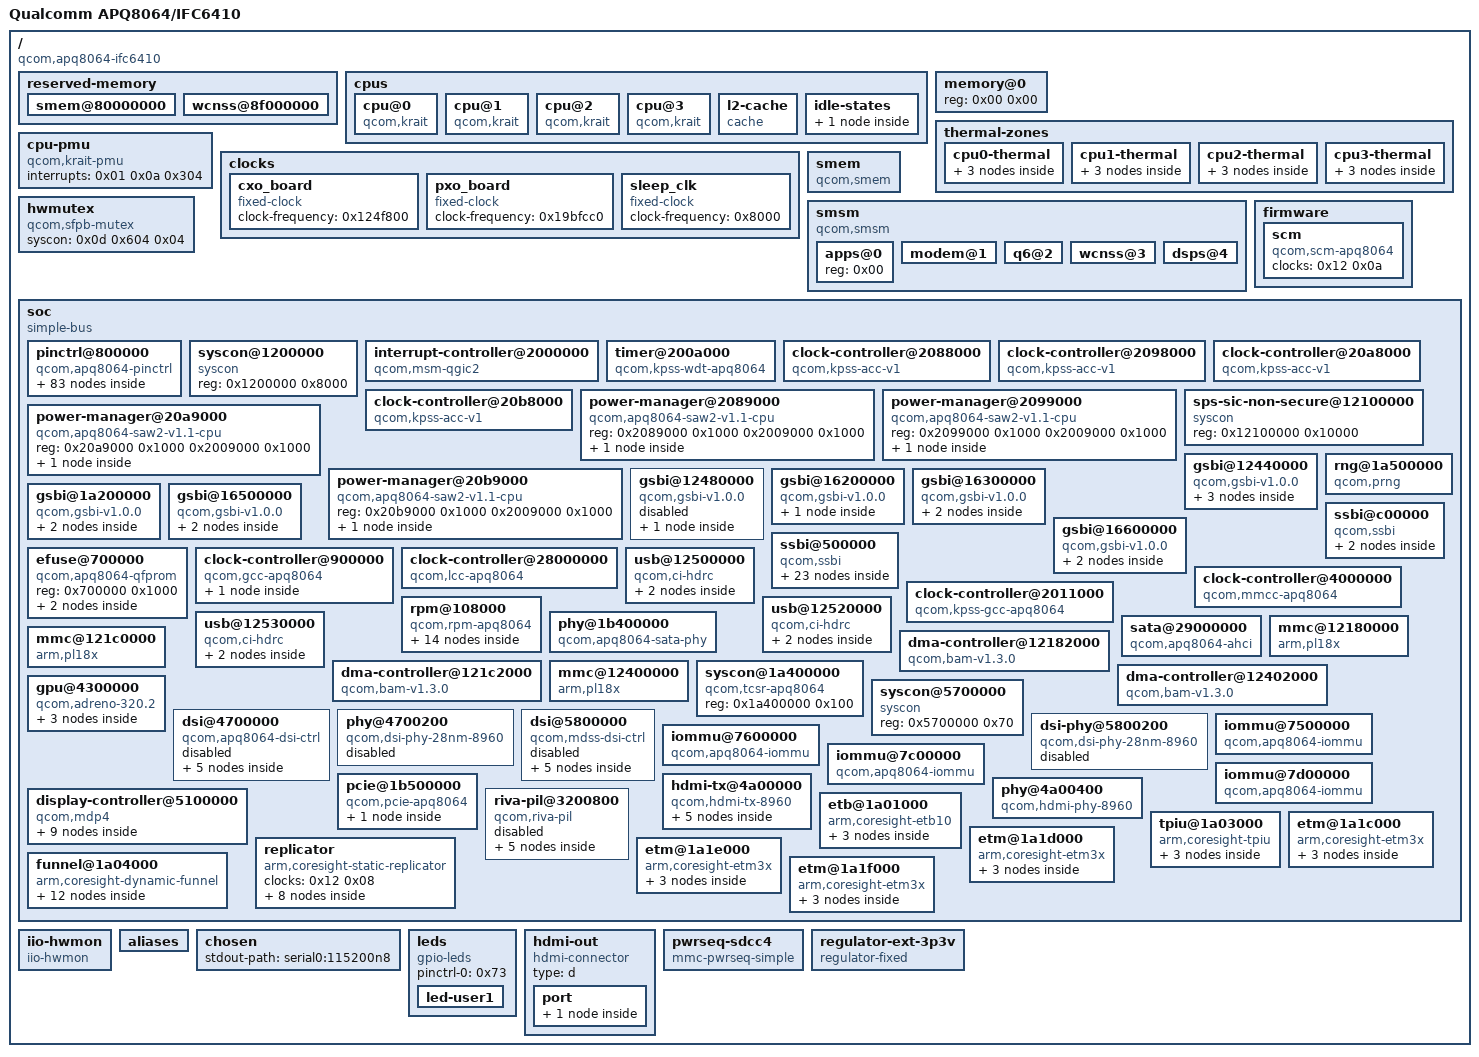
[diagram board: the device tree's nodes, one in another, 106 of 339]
/*
 * Copyright Linux Kernel Team
 *
 * SPDX-License-Identifier: GPL-2.0-only
 *
 * This file is derived from an intermediate build stage of the
 * Linux kernel. The licenses of all input files to this process
 * are compatible with GPL-2.0-only.
 */

/dts-v1/;

/ {
	#address-cells = <0x01>;
	#size-cells = <0x01>;
	model = "Qualcomm APQ8064/IFC6410";
	compatible = "qcom,apq8064-ifc6410", "qcom,apq8064";
	interrupt-parent = <0x01>;

	reserved-memory {
		#address-cells = <0x01>;
		#size-cells = <0x01>;
		ranges;

		smem@80000000 {
			reg = <0x80000000 0x200000>;
			no-map;
			phandle = <0x0e>;
		};

		wcnss@8f000000 {
			reg = <0x8f000000 0x700000>;
			no-map;
			phandle = <0x5d>;
		};
	};

	cpus {
		#address-cells = <0x01>;
		#size-cells = <0x00>;

		cpu@0 {
			compatible = "qcom,krait";
			enable-method = "qcom,kpss-acc-v1";
			device_type = "cpu";
			reg = <0x00>;
			next-level-cache = <0x02>;
			qcom,acc = <0x03>;
			qcom,saw = <0x04>;
			cpu-idle-states = <0x05>;
			phandle = <0x6a>;
		};

		cpu@1 {
			compatible = "qcom,krait";
			enable-method = "qcom,kpss-acc-v1";
			device_type = "cpu";
			reg = <0x01>;
			next-level-cache = <0x02>;
			qcom,acc = <0x06>;
			qcom,saw = <0x07>;
			cpu-idle-states = <0x05>;
			phandle = <0x6c>;
		};

		cpu@2 {
			compatible = "qcom,krait";
			enable-method = "qcom,kpss-acc-v1";
			device_type = "cpu";
			reg = <0x02>;
			next-level-cache = <0x02>;
			qcom,acc = <0x08>;
			qcom,saw = <0x09>;
			cpu-idle-states = <0x05>;
			phandle = <0x6e>;
		};

		cpu@3 {
			compatible = "qcom,krait";
			enable-method = "qcom,kpss-acc-v1";
			device_type = "cpu";
			reg = <0x03>;
			next-level-cache = <0x02>;
			qcom,acc = <0x0a>;
			qcom,saw = <0x0b>;
			cpu-idle-states = <0x05>;
			phandle = <0x70>;
		};

		l2-cache {
			compatible = "cache";
			cache-level = <0x02>;
			cache-unified;
			phandle = <0x02>;
		};

		idle-states {

			cpu-spc {
				compatible = "qcom,idle-state-spc", "arm,idle-state";
				entry-latency-us = <0x190>;
				exit-latency-us = <0x384>;
				min-residency-us = <0xbb8>;
				phandle = <0x05>;
			};
		};
	};

	memory@0 {
		device_type = "memory";
		reg = <0x00 0x00>;
	};

	thermal-zones {

		cpu0-thermal {
			polling-delay-passive = <0xfa>;
			polling-delay = <0x3e8>;
			thermal-sensors = <0x0c 0x07>;
			coefficients = <0x4af 0x00>;

			trips {

				trip0 {
					temperature = <0x124f8>;
					hysteresis = <0x7d0>;
					type = "passive";
				};

				trip1 {
					temperature = <0x1adb0>;
					hysteresis = <0x7d0>;
					type = "critical";
				};
			};
		};

		cpu1-thermal {
			polling-delay-passive = <0xfa>;
			polling-delay = <0x3e8>;
			thermal-sensors = <0x0c 0x08>;
			coefficients = <0x46c 0x00>;

			trips {

				trip0 {
					temperature = <0x124f8>;
					hysteresis = <0x7d0>;
					type = "passive";
				};

				trip1 {
					temperature = <0x1adb0>;
					hysteresis = <0x7d0>;
					type = "critical";
				};
			};
		};

		cpu2-thermal {
			polling-delay-passive = <0xfa>;
			polling-delay = <0x3e8>;
			thermal-sensors = <0x0c 0x09>;
			coefficients = <0x4af 0x00>;

			trips {

				trip0 {
					temperature = <0x124f8>;
					hysteresis = <0x7d0>;
					type = "passive";
				};

				trip1 {
					temperature = <0x1adb0>;
					hysteresis = <0x7d0>;
					type = "critical";
				};
			};
		};

		cpu3-thermal {
			polling-delay-passive = <0xfa>;
			polling-delay = <0x3e8>;
			thermal-sensors = <0x0c 0x0a>;
			coefficients = <0x46c 0x00>;

			trips {

				trip0 {
					temperature = <0x124f8>;
					hysteresis = <0x7d0>;
					type = "passive";
				};

				trip1 {
					temperature = <0x1adb0>;
					hysteresis = <0x7d0>;
					type = "critical";
				};
			};
		};
	};

	cpu-pmu {
		compatible = "qcom,krait-pmu";
		interrupts = <0x01 0x0a 0x304>;
	};

	clocks {

		cxo_board {
			compatible = "fixed-clock";
			#clock-cells = <0x00>;
			clock-frequency = <0x124f800>;
			phandle = <0x2d>;
		};

		pxo_board {
			compatible = "fixed-clock";
			#clock-cells = <0x00>;
			clock-frequency = <0x19bfcc0>;
			phandle = <0x16>;
		};

		sleep_clk {
			compatible = "fixed-clock";
			#clock-cells = <0x00>;
			clock-frequency = <0x8000>;
			phandle = <0x38>;
		};
	};

	hwmutex {
		compatible = "qcom,sfpb-mutex";
		syscon = <0x0d 0x604 0x04>;
		#hwlock-cells = <0x01>;
		phandle = <0x0f>;
	};

	smem {
		compatible = "qcom,smem";
		memory-region = <0x0e>;
		hwlocks = <0x0f 0x03>;
	};

	smsm {
		compatible = "qcom,smsm";
		#address-cells = <0x01>;
		#size-cells = <0x00>;
		qcom,ipc-1 = <0x10 0x08 0x04>;
		qcom,ipc-2 = <0x10 0x08 0x0e>;
		qcom,ipc-3 = <0x10 0x08 0x17>;
		qcom,ipc-4 = <0x11 0x4094 0x00>;

		apps@0 {
			reg = <0x00>;
			#qcom,smem-state-cells = <0x01>;
			phandle = <0x5f>;
		};

		modem@1 {
			reg = <0x01>;
			interrupts = <0x00 0x26 0x01>;
			interrupt-controller;
			#interrupt-cells = <0x02>;
		};

		q6@2 {
			reg = <0x02>;
			interrupts = <0x00 0x59 0x01>;
			interrupt-controller;
			#interrupt-cells = <0x02>;
		};

		wcnss@3 {
			reg = <0x03>;
			interrupts = <0x00 0xcc 0x01>;
			interrupt-controller;
			#interrupt-cells = <0x02>;
			phandle = <0x5c>;
		};

		dsps@4 {
			reg = <0x04>;
			interrupts = <0x00 0x89 0x01>;
			interrupt-controller;
			#interrupt-cells = <0x02>;
		};
	};

	firmware {

		scm {
			compatible = "qcom,scm-apq8064", "qcom,scm";
			clocks = <0x12 0x0a>;
			clock-names = "core";
		};
	};

	soc {
		#address-cells = <0x01>;
		#size-cells = <0x01>;
		ranges;
		compatible = "simple-bus";

		pinctrl@800000 {
			compatible = "qcom,apq8064-pinctrl";
			reg = <0x800000 0x4000>;
			gpio-controller;
			gpio-ranges = <0x13 0x00 0x00 0x5a>;
			#gpio-cells = <0x02>;
			interrupt-controller;
			#interrupt-cells = <0x02>;
			interrupts = <0x00 0x10 0x04>;
			pinctrl-names = "default";
			pinctrl-0 = <0x14>;
			phandle = <0x13>;

			sdc4-gpios {
				phandle = <0x46>;

				pios {
					pins = "gpio63", "gpio64", "gpio65", "gpio66", "gpio67", "gpio68";
					function = "sdc4";
				};
			};

			sdcc1-pin-active {
				phandle = <0x4a>;

				clk {
					pins = "sdc1_clk";
					drive-strengh = <0x10>;
					bias-disable;
				};

				cmd {
					pins = "sdc1_cmd";
					drive-strengh = <0x0a>;
					bias-pull-up;
				};

				data {
					pins = "sdc1_data";
					drive-strengh = <0x0a>;
					bias-pull-up;
				};
			};

			sdcc3-pin-active {

				clk {
					pins = "sdc3_clk";
					drive-strengh = <0x08>;
					bias-disable;
				};

				cmd {
					pins = "sdc3_cmd";
					drive-strengh = <0x08>;
					bias-pull-up;
				};

				data {
					pins = "sdc3_data";
					drive-strengh = <0x08>;
					bias-pull-up;
				};
			};

			ps_hold {
				phandle = <0x14>;

				mux {
					pins = "gpio78";
					function = "ps_hold";
				};
			};

			i2c1 {
				phandle = <0x18>;

				mux {
					pins = "gpio20", "gpio21";
					function = "gsbi1";
				};

				pinconf {
					pins = "gpio20", "gpio21";
					drive-strength = <0x10>;
					bias-disable;
				};
			};

			i2c1_pins_sleep {
				phandle = <0x19>;

				mux {
					pins = "gpio20", "gpio21";
					function = "gpio";
				};

				pinconf {
					pins = "gpio20", "gpio21";
					drive-strength = <0x02>;
					bias-disable;
				};
			};

			gsbi1_uart_2pins {

				mux {
					pins = "gpio18", "gpio19";
					function = "gsbi1";
				};
			};

			gsbi1_uart_4pins {

				mux {
					pins = "gpio18", "gpio19", "gpio20", "gpio21";
					function = "gsbi1";
				};
			};

			i2c2 {
				phandle = <0x1a>;

				mux {
					pins = "gpio24", "gpio25";
					function = "gsbi2";
				};

				pinconf {
					pins = "gpio24", "gpio25";
					drive-strength = <0x10>;
					bias-disable;
				};
			};

			i2c2_pins_sleep {
				phandle = <0x1b>;

				mux {
					pins = "gpio24", "gpio25";
					function = "gpio";
				};

				pinconf {
					pins = "gpio24", "gpio25";
					drive-strength = <0x02>;
					bias-disable;
				};
			};

			i2c3 {
				phandle = <0x1c>;

				mux {
					pins = "gpio8", "gpio9";
					function = "gsbi3";
				};

				pinconf {
					pins = "gpio8", "gpio9";
					drive-strength = <0x10>;
					bias-disable;
				};
			};

			i2c3_pins_sleep {
				phandle = <0x1d>;

				mux {
					pins = "gpio8", "gpio9";
					function = "gpio";
				};

				pinconf {
					pins = "gpio8", "gpio9";
					drive-strength = <0x02>;
					bias-disable;
				};
			};

			i2c4 {
				phandle = <0x1f>;

				mux {
					pins = "gpio12", "gpio13";
					function = "gsbi4";
				};

				pinconf {
					pins = "gpio12", "gpio13";
					drive-strength = <0x10>;
					bias-disable;
				};
			};

			i2c4_pins_sleep {
				phandle = <0x20>;

				mux {
					pins = "gpio12", "gpio13";
					function = "gpio";
				};

				pinconf {
					pins = "gpio12", "gpio13";
					drive-strength = <0x02>;
					bias-disable;
				};
			};

			spi5_default {
				phandle = <0x21>;

				pinmux {
					pins = "gpio51", "gpio52", "gpio54";
					function = "gsbi5";
				};

				pinmux_cs {
					function = "gpio";
					pins = "gpio53";
				};

				pinconf {
					pins = "gpio51", "gpio52", "gpio54";
					drive-strength = <0x10>;
					bias-disable;
				};

				pinconf_cs {
					pins = "gpio53";
					drive-strength = <0x10>;
					bias-disable;
					output-high;
				};
			};

			spi5_sleep {
				phandle = <0x22>;

				pinmux {
					function = "gpio";
					pins = "gpio51", "gpio52", "gpio53", "gpio54";
				};

				pinconf {
					pins = "gpio51", "gpio52", "gpio53", "gpio54";
					drive-strength = <0x02>;
					bias-pull-down;
				};
			};

			i2c6 {
				phandle = <0x24>;

				mux {
					pins = "gpio16", "gpio17";
					function = "gsbi6";
				};

				pinconf {
					pins = "gpio16", "gpio17";
					drive-strength = <0x10>;
					bias-disable;
				};
			};

			i2c6_pins_sleep {
				phandle = <0x25>;

				mux {
					pins = "gpio16", "gpio17";
					function = "gpio";
				};

				pinconf {
					pins = "gpio16", "gpio17";
					drive-strength = <0x02>;
					bias-disable;
				};
			};

			gsbi4-uart-pin-active-state {
				phandle = <0x1e>;

				rx-pins {
					pins = "gpio11";
					function = "gsbi4";
					drive-strength = <0x02>;
					bias-disable;
				};

				tx-pins {
					pins = "gpio10";
					function = "gsbi4";
					drive-strength = <0x04>;
					bias-disable;
				};
			};

			gsbi6_uart_2pins {

				mux {
					pins = "gpio14", "gpio15";
					function = "gsbi6";
				};
			};

			gsbi6_uart_4pins {
				phandle = <0x23>;

				mux {
					pins = "gpio14", "gpio15", "gpio16", "gpio17";
					function = "gsbi6";
				};
			};

			gsbi7_uart_2pins {
				phandle = <0x26>;

				mux {
					pins = "gpio82", "gpio83";
					function = "gsbi7";
				};
			};

			gsbi7_uart_4pins {

				mux {
					pins = "gpio82", "gpio83", "gpio84", "gpio85";
					function = "gsbi7";
				};
			};

			i2c7 {
				phandle = <0x27>;

				mux {
					pins = "gpio84", "gpio85";
					function = "gsbi7";
				};

				pinconf {
					pins = "gpio84", "gpio85";
					drive-strength = <0x10>;
					bias-disable;
				};
			};

			i2c7_pins_sleep {
				phandle = <0x28>;

				mux {
					pins = "gpio84", "gpio85";
					function = "gpio";
				};

				pinconf {
					pins = "gpio84", "gpio85";
					drive-strength = <0x02>;
					bias-disable;
				};
			};

			riva-fm-active {
				pins = "gpio14", "gpio15";
				function = "riva_fm";
			};

			riva-bt-active {
				pins = "gpio16", "gpio17";
				function = "riva_bt";
			};

			riva-wlan-active {
				pins = "gpio64", "gpio65", "gpio66", "gpio67", "gpio68";
				function = "riva_wlan";
				drive-strength = <0x06>;
				bias-pull-down;
			};

			hdmi-pinctrl {
				phandle = <0x55>;

				mux {
					pins = "gpio70", "gpio71", "gpio72";
					function = "hdmi";
				};

				pinconf_ddc {
					pins = "gpio70", "gpio71";
					bias-pull-up;
					drive-strength = <0x02>;
				};

				pinconf_hpd {
					pins = "gpio72";
					bias-pull-down;
					drive-strength = <0x10>;
				};
			};

			card_detect {
				phandle = <0x44>;

				mux {
					pins = "gpio26";
					function = "gpio";
					bias-disable;
				};
			};

			pcie_pinmux {
				phandle = <0x54>;

				mux {
					pins = "gpio27";
					function = "gpio";
				};

				conf {
					pins = "gpio27";
					drive-strength = <0x0c>;
					bias-disable;
				};
			};
		};

		syscon@1200000 {
			compatible = "syscon";
			reg = <0x1200000 0x8000>;
			phandle = <0x0d>;
		};

		interrupt-controller@2000000 {
			compatible = "qcom,msm-qgic2";
			interrupt-controller;
			#interrupt-cells = <0x03>;
			reg = <0x2000000 0x1000 0x2002000 0x1000>;
			phandle = <0x01>;
		};

		timer@200a000 {
			compatible = "qcom,kpss-wdt-apq8064", "qcom,kpss-timer", "qcom,msm-timer";
			interrupts = <0x01 0x01 0x301 0x01 0x02 0x301 0x01 0x03 0x301>;
			reg = <0x200a000 0x100>;
			clock-frequency = <0x19bfcc0>;
			cpu-offset = <0x80000>;
		};

		clock-controller@2088000 {
			compatible = "qcom,kpss-acc-v1";
			reg = <0x2088000 0x1000 0x2008000 0x1000>;
			clocks = <0x15 0x11f 0x16>;
			clock-names = "pll8_vote", "pxo";
			clock-output-names = "acpu0_aux";
			#clock-cells = <0x00>;
			phandle = <0x03>;
		};

		clock-controller@2098000 {
			compatible = "qcom,kpss-acc-v1";
			reg = <0x2098000 0x1000 0x2008000 0x1000>;
			clocks = <0x15 0x11f 0x16>;
			clock-names = "pll8_vote", "pxo";
			clock-output-names = "acpu1_aux";
			#clock-cells = <0x00>;
			phandle = <0x06>;
		};

		clock-controller@20a8000 {
			compatible = "qcom,kpss-acc-v1";
			reg = <0x20a8000 0x1000 0x2008000 0x1000>;
			clocks = <0x15 0x11f 0x16>;
			clock-names = "pll8_vote", "pxo";
			clock-output-names = "acpu2_aux";
			#clock-cells = <0x00>;
			phandle = <0x08>;
		};

		clock-controller@20b8000 {
			compatible = "qcom,kpss-acc-v1";
			reg = <0x20b8000 0x1000 0x2008000 0x1000>;
			clocks = <0x15 0x11f 0x16>;
			clock-names = "pll8_vote", "pxo";
			clock-output-names = "acpu3_aux";
			#clock-cells = <0x00>;
			phandle = <0x0a>;
		};

		power-manager@2089000 {
			compatible = "qcom,apq8064-saw2-v1.1-cpu", "qcom,saw2";
			reg = <0x2089000 0x1000 0x2009000 0x1000>;
			phandle = <0x04>;

			regulator {
				regulator-min-microvolt = <0xcf850>;
				regulator-max-microvolt = <0x13d620>;
			};
		};

		power-manager@2099000 {
			compatible = "qcom,apq8064-saw2-v1.1-cpu", "qcom,saw2";
			reg = <0x2099000 0x1000 0x2009000 0x1000>;
			phandle = <0x07>;

			regulator {
				regulator-min-microvolt = <0xcf850>;
				regulator-max-microvolt = <0x13d620>;
			};
		};

		power-manager@20a9000 {
			compatible = "qcom,apq8064-saw2-v1.1-cpu", "qcom,saw2";
			reg = <0x20a9000 0x1000 0x2009000 0x1000>;
			phandle = <0x09>;

			regulator {
				regulator-min-microvolt = <0xcf850>;
				regulator-max-microvolt = <0x13d620>;
			};
		};

		power-manager@20b9000 {
			compatible = "qcom,apq8064-saw2-v1.1-cpu", "qcom,saw2";
			reg = <0x20b9000 0x1000 0x2009000 0x1000>;
			phandle = <0x0b>;

			regulator {
				regulator-min-microvolt = <0xcf850>;
				regulator-max-microvolt = <0x13d620>;
			};
		};

		sps-sic-non-secure@12100000 {
			compatible = "syscon";
			reg = <0x12100000 0x10000>;
			phandle = <0x11>;
		};

		gsbi@12440000 {
			status = "okay";
			compatible = "qcom,gsbi-v1.0.0";
			cell-index = <0x01>;
			reg = <0x12440000 0x100>;
			clocks = <0x15 0x93>;
			clock-names = "iface";
			#address-cells = <0x01>;
			#size-cells = <0x01>;
			ranges;
			syscon-tcsr = <0x17>;
			qcom,mode = <0x02>;

			serial@12450000 {
				compatible = "qcom,msm-uartdm-v1.3", "qcom,msm-uartdm";
				reg = <0x12450000 0x100 0x12400000 0x03>;
				interrupts = <0x00 0xc1 0x04>;
				clocks = <0x15 0xa0 0x15 0x93>;
				clock-names = "core", "iface";
				status = "disabled";
			};

			i2c@12460000 {
				compatible = "qcom,i2c-qup-v1.1.1";
				pinctrl-0 = <0x18>;
				pinctrl-1 = <0x19>;
				pinctrl-names = "default", "sleep";
				reg = <0x12460000 0x1000>;
				interrupts = <0x00 0xc2 0x04>;
				clocks = <0x15 0xb8 0x15 0x93>;
				clock-names = "core", "iface";
				#address-cells = <0x01>;
				#size-cells = <0x00>;
				status = "okay";
				clock-frequency = <0x30d40>;

				eeprom@52 {
					compatible = "atmel,24c128";
					reg = <0x52>;
					pagesize = <0x20>;
				};
			};
		};

		gsbi@12480000 {
			status = "disabled";
			compatible = "qcom,gsbi-v1.0.0";
			cell-index = <0x02>;
			reg = <0x12480000 0x100>;
			clocks = <0x15 0x94>;
			clock-names = "iface";
			#address-cells = <0x01>;
			#size-cells = <0x01>;
			ranges;
			syscon-tcsr = <0x17>;

			i2c@124a0000 {
				compatible = "qcom,i2c-qup-v1.1.1";
				reg = <0x124a0000 0x1000>;
				pinctrl-0 = <0x1a>;
				pinctrl-1 = <0x1b>;
				pinctrl-names = "default", "sleep";
				interrupts = <0x00 0xc4 0x04>;
				clocks = <0x15 0xba 0x15 0x94>;
				clock-names = "core", "iface";
				#address-cells = <0x01>;
				#size-cells = <0x00>;
				status = "disabled";
			};
		};

		gsbi@16200000 {
			status = "okay";
			compatible = "qcom,gsbi-v1.0.0";
			cell-index = <0x03>;
			reg = <0x16200000 0x100>;
			clocks = <0x15 0x95>;
			clock-names = "iface";
			#address-cells = <0x01>;
			#size-cells = <0x01>;
			ranges;
			qcom,mode = <0x02>;

			i2c@16280000 {
				compatible = "qcom,i2c-qup-v1.1.1";
				pinctrl-0 = <0x1c>;
				pinctrl-1 = <0x1d>;
				pinctrl-names = "default", "sleep";
				reg = <0x16280000 0x1000>;
				interrupts = <0x00 0x97 0x04>;
				clocks = <0x15 0xbc 0x15 0x95>;
				clock-names = "core", "iface";
				#address-cells = <0x01>;
				#size-cells = <0x00>;
				status = "okay";
			};
		};

		gsbi@16300000 {
			status = "okay";
			compatible = "qcom,gsbi-v1.0.0";
			cell-index = <0x04>;
			reg = <0x16300000 0x03>;
			clocks = <0x15 0x96>;
			clock-names = "iface";
			#address-cells = <0x01>;
			#size-cells = <0x01>;
			ranges;
			qcom,mode = <0x02>;

			serial@16340000 {
				compatible = "qcom,msm-uartdm-v1.3", "qcom,msm-uartdm";
				reg = <0x16340000 0x100 0x16300000 0x03>;
				interrupts = <0x00 0x98 0x04>;
				pinctrl-0 = <0x1e>;
				pinctrl-names = "default";
				clocks = <0x15 0xa6 0x15 0x96>;
				clock-names = "core", "iface";
				status = "disabled";
			};

			i2c@16380000 {
				compatible = "qcom,i2c-qup-v1.1.1";
				pinctrl-0 = <0x1f>;
				pinctrl-1 = <0x20>;
				pinctrl-names = "default", "sleep";
				reg = <0x16380000 0x1000>;
				interrupts = <0x00 0x99 0x04>;
				clocks = <0x15 0xbe 0x15 0x96>;
				clock-names = "core", "iface";
				status = "okay";
			};
		};

		gsbi@1a200000 {
			status = "okay";
			compatible = "qcom,gsbi-v1.0.0";
			cell-index = <0x05>;
			reg = <0x1a200000 0x03>;
			clocks = <0x15 0x97>;
			clock-names = "iface";
			#address-cells = <0x01>;
			#size-cells = <0x01>;
			ranges;
			qcom,mode = <0x03>;

			serial@1a240000 {
				compatible = "qcom,msm-uartdm-v1.3", "qcom,msm-uartdm";
				reg = <0x1a240000 0x100 0x1a200000 0x03>;
				interrupts = <0x00 0x9a 0x04>;
				clocks = <0x15 0xa8 0x15 0x97>;
				clock-names = "core", "iface";
				status = "disabled";
			};

			spi@1a280000 {
				compatible = "qcom,spi-qup-v1.1.1";
				reg = <0x1a280000 0x1000>;
				interrupts = <0x00 0x9b 0x04>;
				pinctrl-0 = <0x21>;
				pinctrl-1 = <0x22>;
				pinctrl-names = "default", "sleep";
				clocks = <0x15 0xc0 0x15 0x97>;
				clock-names = "core", "iface";
				status = "okay";
				#address-cells = <0x01>;
				#size-cells = <0x00>;
				num-cs = <0x01>;
				cs-gpios = <0x13 0x35 0x00>;
			};
		};

		gsbi@16500000 {
			status = "okay";
			compatible = "qcom,gsbi-v1.0.0";
			cell-index = <0x06>;
			reg = <0x16500000 0x03>;
			clocks = <0x15 0x98>;
			clock-names = "iface";
			#address-cells = <0x01>;
			#size-cells = <0x01>;
			ranges;
			qcom,mode = <0x04>;

			serial@16540000 {
				compatible = "qcom,msm-uartdm-v1.3", "qcom,msm-uartdm";
				reg = <0x16540000 0x100 0x16500000 0x03>;
				interrupts = <0x00 0x9c 0x04>;
				clocks = <0x15 0xaa 0x15 0x98>;
				clock-names = "core", "iface";
				status = "okay";
				pinctrl-names = "default";
				pinctrl-0 = <0x23>;
			};

			i2c@16580000 {
				compatible = "qcom,i2c-qup-v1.1.1";
				pinctrl-0 = <0x24>;
				pinctrl-1 = <0x25>;
				pinctrl-names = "default", "sleep";
				reg = <0x16580000 0x1000>;
				interrupts = <0x00 0x9d 0x04>;
				clocks = <0x15 0xc2 0x15 0x98>;
				clock-names = "core", "iface";
				status = "disabled";
			};
		};

		gsbi@16600000 {
			status = "okay";
			compatible = "qcom,gsbi-v1.0.0";
			cell-index = <0x07>;
			reg = <0x16600000 0x100>;
			clocks = <0x15 0x99>;
			clock-names = "iface";
			#address-cells = <0x01>;
			#size-cells = <0x01>;
			ranges;
			syscon-tcsr = <0x17>;
			qcom,mode = <0x06>;

			serial@16640000 {
				compatible = "qcom,msm-uartdm-v1.3", "qcom,msm-uartdm";
				reg = <0x16640000 0x1000 0x16600000 0x1000>;
				interrupts = <0x00 0x9e 0x04>;
				clocks = <0x15 0xac 0x15 0x99>;
				clock-names = "core", "iface";
				status = "okay";
				pinctrl-names = "default";
				pinctrl-0 = <0x26>;
			};

			i2c@16680000 {
				compatible = "qcom,i2c-qup-v1.1.1";
				pinctrl-0 = <0x27>;
				pinctrl-1 = <0x28>;
				pinctrl-names = "default", "sleep";
				reg = <0x16680000 0x1000>;
				interrupts = <0x00 0x9f 0x04>;
				clocks = <0x15 0xc4 0x15 0x99>;
				clock-names = "core", "iface";
				status = "disabled";
			};
		};

		rng@1a500000 {
			compatible = "qcom,prng";
			reg = <0x1a500000 0x200>;
			clocks = <0x15 0x108>;
			clock-names = "core";
		};

		ssbi@c00000 {
			compatible = "qcom,ssbi";
			reg = <0xc00000 0x1000>;
			qcom,controller-type = "pmic-arbiter";

			pmic {
				compatible = "qcom,pm8821";
				interrupt-controller;
				#interrupt-cells = <0x02>;
				#address-cells = <0x01>;
				#size-cells = <0x00>;
				interrupts-extended = <0x13 0x4c 0x08>;

				mpps@50 {
					compatible = "qcom,pm8821-mpp", "qcom,ssbi-mpp";
					reg = <0x50>;
					gpio-controller;
					#gpio-cells = <0x02>;
					gpio-ranges = <0x29 0x00 0x00 0x04>;
					interrupt-controller;
					#interrupt-cells = <0x02>;
					phandle = <0x29>;
				};
			};
		};

		ssbi@500000 {
			compatible = "qcom,ssbi";
			reg = <0x500000 0x1000>;
			qcom,controller-type = "pmic-arbiter";

			pmic {
				compatible = "qcom,pm8921";
				#interrupt-cells = <0x02>;
				interrupt-controller;
				#address-cells = <0x01>;
				#size-cells = <0x00>;
				interrupts-extended = <0x13 0x4a 0x08>;
				phandle = <0x2a>;

				pwrkey@1c {
					compatible = "qcom,pm8921-pwrkey";
					reg = <0x1c>;
					interrupts-extended = <0x2a 0x32 0x01 0x2a 0x33 0x01>;
					debounce = <0x3d09>;
					pull-up;
				};

				mpps@50 {
					compatible = "qcom,pm8921-mpp", "qcom,ssbi-mpp";
					reg = <0x50>;
					gpio-controller;
					#gpio-cells = <0x02>;
					gpio-ranges = <0x2b 0x00 0x00 0x0c>;
					interrupt-controller;
					#interrupt-cells = <0x02>;
					phandle = <0x2b>;
				};

				rtc@11d {
					compatible = "qcom,pm8921-rtc";
					reg = <0x11d>;
					interrupts-extended = <0x2a 0x27 0x01>;
					allow-set-time;
				};

				keypad@148 {
					compatible = "qcom,pm8921-keypad";
					reg = <0x148>;
					interrupts-extended = <0x2a 0x4a 0x01 0x2a 0x4b 0x01>;
					debounce = <0x0f>;
					scan-delay = <0x20>;
					row-hold = <0x1656c>;
					status = "disabled";
				};

				gpio@150 {
					compatible = "qcom,pm8921-gpio", "qcom,ssbi-gpio";
					reg = <0x150>;
					interrupt-controller;
					#interrupt-cells = <0x02>;
					gpio-controller;
					gpio-ranges = <0x2c 0x00 0x00 0x2c>;
					#gpio-cells = <0x02>;
					phandle = <0x2c>;

					wlan-gpios-state {
						phandle = <0x75>;

						pinconf {
							pins = "gpio43";
							function = "normal";
							bias-disable;
							power-source = <0x02>;
						};
					};

					nled-state {
						phandle = <0x73>;

						pinconf {
							pins = "gpio18";
							function = "normal";
							bias-disable;
							power-source = <0x02>;
						};
					};
				};

				xoadc@197 {
					compatible = "qcom,pm8921-adc";
					reg = <0x197>;
					interrupts-extended = <0x2a 0x4e 0x01>;
					#address-cells = <0x02>;
					#size-cells = <0x00>;
					#io-channel-cells = <0x02>;
					phandle = <0x72>;

					adc-channel@0 {
						reg = <0x00 0x00>;
					};

					adc-channel@1 {
						reg = <0x00 0x01>;
					};

					adc-channel@2 {
						reg = <0x00 0x02>;
					};

					adc-channel@4 {
						reg = <0x00 0x04>;
					};

					adc-channel@8 {
						reg = <0x00 0x08>;
					};

					adc-channel@9 {
						reg = <0x00 0x09>;
					};

					adc-channel@a {
						reg = <0x00 0x0a>;
					};

					adc-channel@b {
						reg = <0x00 0x0b>;
					};

					adc-channel@c {
						reg = <0x00 0x0c>;
					};

					adc-channel@d {
						reg = <0x00 0x0d>;
					};

					adc-channel@e {
						reg = <0x00 0x0e>;
					};

					adc-channel@f {
						reg = <0x00 0x0f>;
					};
				};
			};
		};

		efuse@700000 {
			compatible = "qcom,apq8064-qfprom", "qcom,qfprom";
			reg = <0x700000 0x1000>;
			#address-cells = <0x01>;
			#size-cells = <0x01>;

			calib@404 {
				reg = <0x404 0x10>;
				phandle = <0x2f>;
			};

			backup_calib@414 {
				reg = <0x414 0x10>;
				phandle = <0x30>;
			};
		};

		clock-controller@900000 {
			compatible = "qcom,gcc-apq8064", "syscon";
			reg = <0x900000 0x4000>;
			#clock-cells = <0x01>;
			#reset-cells = <0x01>;
			clocks = <0x2d 0x16 0x2e 0x00>;
			clock-names = "cxo", "pxo", "pll4";
			phandle = <0x15>;

			thermal-sensor {
				compatible = "qcom,msm8960-tsens";
				nvmem-cells = <0x2f 0x30>;
				nvmem-cell-names = "calib", "calib_backup";
				interrupts = <0x00 0xb2 0x04>;
				interrupt-names = "uplow";
				#qcom,sensors = <0x0b>;
				#thermal-sensor-cells = <0x01>;
				phandle = <0x0c>;
			};
		};

		clock-controller@28000000 {
			compatible = "qcom,lcc-apq8064";
			reg = <0x28000000 0x1000>;
			#clock-cells = <0x01>;
			#reset-cells = <0x01>;
			clocks = <0x16 0x15 0x118 0x00 0x00 0x00 0x00 0x00 0x00>;
			clock-names = "pxo", "pll4_vote", "mi2s_codec_clk", "codec_i2s_mic_codec_clk", "spare_i2s_mic_codec_clk", "codec_i2s_spkr_codec_clk", "spare_i2s_spkr_codec_clk", "pcm_codec_clk";
			phandle = <0x2e>;
		};

		clock-controller@4000000 {
			compatible = "qcom,mmcc-apq8064";
			reg = <0x4000000 0x1000>;
			#clock-cells = <0x01>;
			#power-domain-cells = <0x01>;
			#reset-cells = <0x01>;
			clocks = <0x16 0x15 0x116 0x15 0x11f 0x31 0x01 0x31 0x00 0x32 0x01 0x32 0x00 0x33>;
			clock-names = "pxo", "pll3", "pll8_vote", "dsi1pll", "dsi1pllbyte", "dsi2pll", "dsi2pllbyte", "hdmipll";
			phandle = <0x4d>;
		};

		clock-controller@2011000 {
			compatible = "qcom,kpss-gcc-apq8064", "qcom,kpss-gcc", "syscon";
			reg = <0x2011000 0x1000>;
			clocks = <0x15 0x11f 0x16>;
			clock-names = "pll8_vote", "pxo";
			#clock-cells = <0x00>;
			phandle = <0x10>;
		};

		rpm@108000 {
			compatible = "qcom,rpm-apq8064";
			reg = <0x108000 0x1000>;
			qcom,ipc = <0x10 0x08 0x02>;
			interrupts = <0x00 0x13 0x01 0x00 0x15 0x01 0x00 0x16 0x01>;
			interrupt-names = "ack", "err", "wakeup";

			clock-controller {
				compatible = "qcom,rpmcc-apq8064", "qcom,rpmcc";
				#clock-cells = <0x01>;
				clocks = <0x16 0x2d>;
				clock-names = "pxo", "cxo";
				phandle = <0x12>;
			};

			regulators {
				compatible = "qcom,rpm-pm8921-regulators";
				vin_lvs1_3_6-supply = <0x34>;
				vin_lvs2-supply = <0x35>;
				vin_lvs4_5_7-supply = <0x34>;
				vdd_l1_l2_l12_l18-supply = <0x34>;
				vdd_l24-supply = <0x35>;
				vdd_l25-supply = <0x35>;
				vdd_l26-supply = <0x36>;
				vdd_l27-supply = <0x36>;
				vdd_l28-supply = <0x36>;

				s1 {
					regulator-always-on;
					regulator-min-microvolt = <0x12b128>;
					regulator-max-microvolt = <0x12b128>;
					qcom,switch-mode-frequency = <0x30d400>;
					bias-pull-down;
					phandle = <0x35>;
				};

				s3 {
					regulator-min-microvolt = <0xf4240>;
					regulator-max-microvolt = <0x155cc0>;
					qcom,switch-mode-frequency = "", "I>";
					phandle = <0x52>;
				};

				s4 {
					regulator-min-microvolt = <0x1b7740>;
					regulator-max-microvolt = <0x1b7740>;
					qcom,switch-mode-frequency = <0x30d400>;
					phandle = <0x34>;
				};

				s7 {
					regulator-min-microvolt = <0x13d620>;
					regulator-max-microvolt = <0x13d620>;
					qcom,switch-mode-frequency = <0x30d400>;
					phandle = <0x36>;
				};

				l3 {
					regulator-min-microvolt = <0x2e8a10>;
					regulator-max-microvolt = <0x325aa0>;
					bias-pull-down;
					phandle = <0x3a>;
				};

				l4 {
					regulator-min-microvolt = <0xf4240>;
					regulator-max-microvolt = <0x1b7740>;
					bias-pull-down;
					phandle = <0x3b>;
				};

				l5 {
					regulator-min-microvolt = <0x29f630>;
					regulator-max-microvolt = <0x2dc6c0>;
					bias-pull-down;
					phandle = <0x4c>;
				};

				l6 {
					regulator-min-microvolt = <0x2d0370>;
					regulator-max-microvolt = <0x2d0370>;
					bias-pull-down;
					phandle = <0x43>;
				};

				l23 {
					regulator-min-microvolt = <0x19f0a0>;
					regulator-max-microvolt = <0x1cfde0>;
					bias-pull-down;
					phandle = <0x3e>;
				};

				lvs1 {
					bias-pull-down;
					phandle = <0x48>;
				};

				lvs6 {
					bias-pull-down;
					phandle = <0x53>;
				};

				hdmi-switch {
					bias-pull-down;
					phandle = <0x56>;
				};
			};
		};

		usb@12500000 {
			compatible = "qcom,ci-hdrc";
			reg = <0x12500000 0x200 0x12500200 0x200>;
			interrupts = <0x00 0x64 0x04>;
			clocks = <0x15 0x80 0x15 0x7e>;
			clock-names = "core", "iface";
			assigned-clocks = <0x15 0x80>;
			assigned-clock-rates = <0x3938700>;
			resets = <0x15 0x40>;
			reset-names = "core";
			phy_type = "ulpi";
			ahb-burst-config = <0x00>;
			phys = <0x37>;
			phy-names = "usb-phy";
			status = "okay";
			#reset-cells = <0x01>;
			dr_mode = "otg";
			phandle = <0x39>;

			ulpi {

				phy {
					compatible = "qcom,usb-hs-phy-apq8064", "qcom,usb-hs-phy";
					clocks = <0x38 0x2d>;
					clock-names = "sleep", "ref";
					resets = <0x39 0x00>;
					reset-names = "por";
					#phy-cells = <0x00>;
					v3p3-supply = <0x3a>;
					v1p8-supply = <0x3b>;
					phandle = <0x37>;
				};
			};
		};

		usb@12520000 {
			compatible = "qcom,ci-hdrc";
			reg = <0x12520000 0x200 0x12520200 0x200>;
			interrupts = <0x00 0xbc 0x04>;
			clocks = <0x15 0x129 0x15 0x127>;
			clock-names = "core", "iface";
			assigned-clocks = <0x15 0x129>;
			assigned-clock-rates = <0x3938700>;
			resets = <0x15 0x64>;
			reset-names = "core";
			phy_type = "ulpi";
			ahb-burst-config = <0x00>;
			phys = <0x3c>;
			phy-names = "usb-phy";
			status = "okay";
			#reset-cells = <0x01>;
			dr_mode = "host";
			phandle = <0x3d>;

			ulpi {

				phy {
					compatible = "qcom,usb-hs-phy-apq8064", "qcom,usb-hs-phy";
					#phy-cells = <0x00>;
					clocks = <0x38 0x2d>;
					clock-names = "sleep", "ref";
					resets = <0x3d 0x00>;
					reset-names = "por";
					v3p3-supply = <0x3a>;
					v1p8-supply = <0x3e>;
					phandle = <0x3c>;
				};
			};
		};

		usb@12530000 {
			compatible = "qcom,ci-hdrc";
			reg = <0x12530000 0x200 0x12530200 0x200>;
			interrupts = <0x00 0xd7 0x04>;
			clocks = <0x15 0x12c 0x15 0x12a>;
			clock-names = "core", "iface";
			assigned-clocks = <0x15 0x12c>;
			assigned-clock-rates = <0x3938700>;
			resets = <0x15 0x65>;
			reset-names = "core";
			phy_type = "ulpi";
			ahb-burst-config = <0x00>;
			phys = <0x3f>;
			phy-names = "usb-phy";
			status = "okay";
			#reset-cells = <0x01>;
			dr_mode = "host";
			phandle = <0x40>;

			ulpi {

				phy {
					compatible = "qcom,usb-hs-phy-apq8064", "qcom,usb-hs-phy";
					#phy-cells = <0x00>;
					clocks = <0x38 0x2d>;
					clock-names = "sleep", "ref";
					resets = <0x40 0x00>;
					reset-names = "por";
					v3p3-supply = <0x3a>;
					v1p8-supply = <0x3e>;
					phandle = <0x3f>;
				};
			};
		};

		phy@1b400000 {
			compatible = "qcom,apq8064-sata-phy";
			status = "okay";
			reg = <0x1b400000 0x200>;
			reg-names = "phy_mem";
			clocks = <0x15 0x12d>;
			clock-names = "cfg";
			#phy-cells = <0x00>;
			phandle = <0x41>;
		};

		sata@29000000 {
			compatible = "qcom,apq8064-ahci", "generic-ahci";
			status = "okay";
			reg = <0x29000000 0x180>;
			interrupts = <0x00 0xd1 0x04>;
			clocks = <0x15 0x3b 0x15 0xed 0x15 0x12e 0x15 0xef 0x15 0xf0>;
			clock-names = "slave_iface", "iface", "bus", "rxoob", "core_pmalive";
			assigned-clocks = <0x15 0xef 0x15 0xf0>;
			assigned-clock-rates = <0x5f5e100 0x5f5e100>;
			phys = <0x41>;
			phy-names = "sata-phy";
			ports-implemented = <0x01>;
			target-supply = <0x34>;
		};

		mmc@12180000 {
			compatible = "arm,pl18x", "arm,primecell";
			arm,primecell-periphid = <0x51180>;
			status = "okay";
			reg = <0x12180000 0x2000>;
			interrupts = <0x00 0x66 0x04>;
			clocks = <0x15 0x7a 0x15 0x70>;
			clock-names = "mclk", "apb_pclk";
			bus-width = <0x04>;
			cap-sd-highspeed;
			cap-mmc-highspeed;
			max-frequency = <0xb71b000>;
			no-1-8-v;
			dmas = <0x42 0x02 0x42 0x01>;
			dma-names = "tx", "rx";
			vmmc-supply = <0x43>;
			pinctrl-names = "default";
			pinctrl-0 = <0x44>;
			cd-gpios = <0x13 0x1a 0x01>;
		};

		dma-controller@12182000 {
			compatible = "qcom,bam-v1.3.0";
			reg = <0x12182000 0x8000>;
			interrupts = <0x00 0x60 0x04>;
			clocks = <0x15 0x70>;
			clock-names = "bam_clk";
			#dma-cells = <0x01>;
			qcom,ee = <0x00>;
			phandle = <0x42>;
		};

		mmc@121c0000 {
			compatible = "arm,pl18x", "arm,primecell";
			arm,primecell-periphid = <0x51180>;
			status = "okay";
			reg = <0x121c0000 0x2000>;
			interrupts = <0x00 0x65 0x04>;
			clocks = <0x15 0x7b 0x15 0x71>;
			clock-names = "mclk", "apb_pclk";
			bus-width = <0x04>;
			cap-sd-highspeed;
			cap-mmc-highspeed;
			max-frequency = <0x2dc6c00>;
			dmas = <0x45 0x02 0x45 0x01>;
			dma-names = "tx", "rx";
			pinctrl-names = "default";
			pinctrl-0 = <0x46>;
			vmmc-supply = <0x47>;
			vqmmc-supply = <0x48>;
			mmc-pwrseq = <0x49>;
		};

		dma-controller@121c2000 {
			compatible = "qcom,bam-v1.3.0";
			reg = <0x121c2000 0x8000>;
			interrupts = <0x00 0x5f 0x04>;
			clocks = <0x15 0x71>;
			clock-names = "bam_clk";
			#dma-cells = <0x01>;
			qcom,ee = <0x00>;
			phandle = <0x45>;
		};

		mmc@12400000 {
			status = "okay";
			compatible = "arm,pl18x", "arm,primecell";
			pinctrl-names = "default";
			pinctrl-0 = <0x4a>;
			arm,primecell-periphid = <0x51180>;
			reg = <0x12400000 0x2000>;
			interrupts = <0x00 0x68 0x04>;
			clocks = <0x15 0x78 0x15 0x6e>;
			clock-names = "mclk", "apb_pclk";
			bus-width = <0x08>;
			max-frequency = <0x5b8d800>;
			non-removable;
			cap-sd-highspeed;
			cap-mmc-highspeed;
			dmas = <0x4b 0x02 0x4b 0x01>;
			dma-names = "tx", "rx";
			vmmc-supply = <0x4c>;
			vqmmc-supply = <0x34>;
		};

		dma-controller@12402000 {
			compatible = "qcom,bam-v1.3.0";
			reg = <0x12402000 0x8000>;
			interrupts = <0x00 0x62 0x04>;
			clocks = <0x15 0x6e>;
			clock-names = "bam_clk";
			#dma-cells = <0x01>;
			qcom,ee = <0x00>;
			phandle = <0x4b>;
		};

		syscon@1a400000 {
			compatible = "qcom,tcsr-apq8064", "syscon";
			reg = <0x1a400000 0x100>;
			phandle = <0x17>;
		};

		gpu@4300000 {
			compatible = "qcom,adreno-320.2", "qcom,adreno";
			reg = <0x4300000 0x20000>;
			reg-names = "kgsl_3d0_reg_memory";
			interrupts = <0x00 0x50 0x04>;
			interrupt-names = "kgsl_3d0_irq";
			clock-names = "core", "iface", "mem", "mem_iface";
			clocks = <0x4d 0x47 0x4d 0x16 0x4d 0x21 0x4d 0x13>;
			iommus = <0x4e 0x00 0x4e 0x01 0x4e 0x02 0x4e 0x03 0x4e 0x04 0x4e 0x05 0x4e 0x06 0x4e 0x07 0x4e 0x08 0x4e 0x09 0x4e 0x0a 0x4e 0x0b 0x4e 0x0c 0x4e 0x0d 0x4e 0x0e 0x4e 0x0f 0x4e 0x10 0x4e 0x11 0x4e 0x12 0x4e 0x13 0x4e 0x14 0x4e 0x15 0x4e 0x16 0x4e 0x17 0x4e 0x18 0x4e 0x19 0x4e 0x1a 0x4e 0x1b 0x4e 0x1c 0x4e 0x1d 0x4e 0x1e 0x4e 0x1f 0x4f 0x00 0x4f 0x01 0x4f 0x02 0x4f 0x03 0x4f 0x04 0x4f 0x05 0x4f 0x06 0x4f 0x07 0x4f 0x08 0x4f 0x09 0x4f 0x0a 0x4f 0x0b 0x4f 0x0c 0x4f 0x0d 0x4f 0x0e 0x4f 0x0f 0x4f 0x10 0x4f 0x11 0x4f 0x12 0x4f 0x13 0x4f 0x14 0x4f 0x15 0x4f 0x16 0x4f 0x17 0x4f 0x18 0x4f 0x19 0x4f 0x1a 0x4f 0x1b 0x4f 0x1c 0x4f 0x1d 0x4f 0x1e 0x4f 0x1f>;
			operating-points-v2 = <0x50>;

			opp-table {
				compatible = "operating-points-v2";
				phandle = <0x50>;

				opp-450000000 {
					opp-hz = <0x00 0x1ad27480>;
				};

				opp-27000000 {
					opp-hz = <0x00 0x19bfcc0>;
				};
			};
		};

		syscon@5700000 {
			compatible = "syscon";
			reg = <0x5700000 0x70>;
			phandle = <0x51>;
		};

		dsi@4700000 {
			compatible = "qcom,apq8064-dsi-ctrl", "qcom,mdss-dsi-ctrl";
			#address-cells = <0x01>;
			#size-cells = <0x00>;
			interrupts = <0x00 0x52 0x04>;
			reg = <0x4700000 0x200>;
			reg-names = "dsi_ctrl";
			clocks = <0x4d 0x11 0x4d 0x08 0x4d 0x04 0x4d 0x39 0x4d 0x54 0x4d 0x6a 0x4d 0x58>;
			clock-names = "iface", "bus", "core_mmss", "src", "byte", "pixel", "core";
			assigned-clocks = <0x4d 0x53 0x4d 0x57 0x4d 0x38 0x4d 0x69>;
			assigned-clock-parents = <0x31 0x00 0x31 0x00 0x31 0x01 0x31 0x01>;
			syscon-sfpb = <0x51>;
			phys = <0x31>;
			status = "disabled";

			ports {
				#address-cells = <0x01>;
				#size-cells = <0x00>;

				port@0 {
					reg = <0x00>;

					endpoint {
					};
				};

				port@1 {
					reg = <0x01>;

					endpoint {
					};
				};
			};
		};

		phy@4700200 {
			compatible = "qcom,dsi-phy-28nm-8960";
			#clock-cells = <0x01>;
			#phy-cells = <0x00>;
			reg = <0x4700200 0x100 0x4700300 0x200 0x4700500 0x5c>;
			reg-names = "dsi_pll", "dsi_phy", "dsi_phy_regulator";
			clock-names = "iface", "ref";
			clocks = <0x4d 0x11 0x16>;
			status = "disabled";
			phandle = <0x31>;
		};

		dsi@5800000 {
			compatible = "qcom,mdss-dsi-ctrl";
			interrupts = <0x00 0xa6 0x04>;
			reg = <0x5800000 0x200>;
			reg-names = "dsi_ctrl";
			clocks = <0x4d 0x09 0x4d 0x05 0x4d 0x04 0x4d 0x52 0x4d 0x56 0x4d 0x50 0x4d 0x5a>;
			clock-names = "iface", "bus", "core_mmss", "src", "byte", "pixel", "core";
			assigned-clocks = <0x4d 0x55 0x4d 0x59 0x4d 0x51 0x4d 0x4f>;
			assigned-clock-parents = <0x32 0x00 0x32 0x00 0x32 0x01 0x32 0x01>;
			syscon-sfpb = <0x51>;
			phys = <0x32>;
			#address-cells = <0x01>;
			#size-cells = <0x00>;
			status = "disabled";

			ports {
				#address-cells = <0x01>;
				#size-cells = <0x00>;

				port@0 {
					reg = <0x00>;

					endpoint {
					};
				};

				port@1 {
					reg = <0x01>;

					endpoint {
					};
				};
			};
		};

		dsi-phy@5800200 {
			compatible = "qcom,dsi-phy-28nm-8960";
			reg = <0x5800200 0x100 0x5800300 0x200 0x5800500 0x5c>;
			reg-names = "dsi_pll", "dsi_phy", "dsi_phy_regulator";
			clock-names = "iface", "ref";
			clocks = <0x4d 0x09 0x16>;
			#clock-cells = <0x01>;
			#phy-cells = <0x00>;
			status = "disabled";
			phandle = <0x32>;
		};

		iommu@7500000 {
			compatible = "qcom,apq8064-iommu";
			#iommu-cells = <0x01>;
			clock-names = "smmu_pclk", "iommu_clk";
			clocks = <0x4d 0x0b 0x4d 0x1e>;
			reg = <0x7500000 0x100000>;
			interrupts = <0x00 0x3f 0x04 0x00 0x40 0x04>;
			qcom,ncb = <0x02>;
			phandle = <0x59>;
		};

		iommu@7600000 {
			compatible = "qcom,apq8064-iommu";
			#iommu-cells = <0x01>;
			clock-names = "smmu_pclk", "iommu_clk";
			clocks = <0x4d 0x0b 0x4d 0x1e>;
			reg = <0x7600000 0x100000>;
			interrupts = <0x00 0x3d 0x04 0x00 0x3e 0x04>;
			qcom,ncb = <0x02>;
			phandle = <0x5a>;
		};

		iommu@7c00000 {
			compatible = "qcom,apq8064-iommu";
			#iommu-cells = <0x01>;
			clock-names = "smmu_pclk", "iommu_clk";
			clocks = <0x4d 0x0b 0x4d 0x21>;
			reg = <0x7c00000 0x100000>;
			interrupts = <0x00 0x45 0x04 0x00 0x46 0x04>;
			qcom,ncb = <0x03>;
			phandle = <0x4e>;
		};

		iommu@7d00000 {
			compatible = "qcom,apq8064-iommu";
			#iommu-cells = <0x01>;
			clock-names = "smmu_pclk", "iommu_clk";
			clocks = <0x4d 0x0b 0x4d 0x21>;
			reg = <0x7d00000 0x100000>;
			interrupts = <0x00 0xd2 0x04 0x00 0xd3 0x04>;
			qcom,ncb = <0x03>;
			phandle = <0x4f>;
		};

		pcie@1b500000 {
			compatible = "qcom,pcie-apq8064";
			reg = <0x1b500000 0x1000 0x1b502000 0x80 0x1b600000 0x100 0xff00000 0x100000>;
			reg-names = "dbi", "elbi", "parf", "config";
			device_type = "pci";
			linux,pci-domain = <0x00>;
			bus-range = <0x00 0xff>;
			num-lanes = <0x01>;
			#address-cells = <0x03>;
			#size-cells = <0x02>;
			ranges = <0x81000000 0x00 0x00 0xfe00000 0x00 0x100000 0x82000000 0x00 0x8000000 0x8000000 0x00 0x7e00000>;
			interrupts = <0x00 0xee 0x04>;
			interrupt-names = "msi";
			#interrupt-cells = <0x01>;
			interrupt-map-mask = <0x00 0x00 0x00 0x07>;
			interrupt-map = <0x00 0x00 0x00 0x01 0x01 0x00 0x24 0x04 0x00 0x00 0x00 0x02 0x01 0x00 0x25 0x04 0x00 0x00 0x00 0x03 0x01 0x00 0x26 0x04 0x00 0x00 0x00 0x04 0x01 0x00 0x27 0x04>;
			clocks = <0x15 0x2b 0x15 0x2e 0x15 0x2d>;
			clock-names = "core", "iface", "phy";
			resets = <0x15 0x6c 0x15 0x6b 0x15 0x6a 0x15 0x69 0x15 0x68>;
			reset-names = "axi", "ahb", "por", "pci", "phy";
			status = "okay";
			vdda-supply = <0x52>;
			vdda_phy-supply = <0x53>;
			vdda_refclk-supply = <0x47>;
			pinctrl-0 = <0x54>;
			pinctrl-names = "default";
			perst-gpios = <0x13 0x1b 0x01>;

			pcie@0 {
				device_type = "pci";
				reg = <0x00 0x00 0x00 0x00 0x00>;
				bus-range = <0x01 0xff>;
				#address-cells = <0x03>;
				#size-cells = <0x02>;
				ranges;
			};
		};

		hdmi-tx@4a00000 {
			compatible = "qcom,hdmi-tx-8960";
			pinctrl-names = "default";
			pinctrl-0 = <0x55>;
			reg = <0x4a00000 0x2f0>;
			reg-names = "core_physical";
			interrupts = <0x00 0x4f 0x04>;
			clocks = <0x4d 0x3e 0x4d 0x0c 0x4d 0x15>;
			clock-names = "core", "master_iface", "slave_iface";
			phys = <0x33>;
			status = "okay";
			core-vdda-supply = <0x56>;
			hpd-gpios = <0x13 0x48 0x00>;

			ports {
				#address-cells = <0x01>;
				#size-cells = <0x00>;

				port@0 {
					reg = <0x00>;

					endpoint {
						remote-endpoint = <0x57>;
						phandle = <0x5b>;
					};
				};

				port@1 {
					reg = <0x01>;

					endpoint {
						remote-endpoint = <0x58>;
						phandle = <0x74>;
					};
				};
			};
		};

		phy@4a00400 {
			compatible = "qcom,hdmi-phy-8960";
			reg = <0x4a00400 0x60 0x4a00500 0x100>;
			reg-names = "hdmi_phy", "hdmi_pll";
			clocks = <0x4d 0x15>;
			clock-names = "slave_iface";
			#phy-cells = <0x00>;
			#clock-cells = <0x00>;
			status = "okay";
			core-vdda-supply = <0x56>;
			phandle = <0x33>;
		};

		display-controller@5100000 {
			compatible = "qcom,mdp4";
			reg = <0x5100000 0xf0000>;
			interrupts = <0x00 0x4b 0x04>;
			clocks = <0x4d 0x4d 0x4d 0x10 0x4d 0x1e 0x4d 0x4e 0x4d 0x5f 0x4d 0x60>;
			clock-names = "core_clk", "iface_clk", "bus_clk", "lut_clk", "hdmi_clk", "tv_clk";
			iommus = <0x59 0x00 0x59 0x02 0x5a 0x00 0x5a 0x02>;
			status = "okay";

			ports {
				#address-cells = <0x01>;
				#size-cells = <0x00>;

				port@0 {
					reg = <0x00>;

					endpoint {
					};
				};

				port@1 {
					reg = <0x01>;

					endpoint {
					};
				};

				port@2 {
					reg = <0x02>;

					endpoint {
					};
				};

				port@3 {
					reg = <0x03>;

					endpoint {
						remote-endpoint = <0x5b>;
						phandle = <0x57>;
					};
				};
			};
		};

		riva-pil@3200800 {
			compatible = "qcom,riva-pil";
			reg = <0x3200800 0x1000 0x3202000 0x2000 0x3204000 0x100>;
			reg-names = "ccu", "dxe", "pmu";
			interrupts-extended = <0x01 0x00 0xc7 0x01 0x5c 0x06 0x01>;
			interrupt-names = "wdog", "fatal";
			memory-region = <0x5d>;
			status = "disabled";
			phandle = <0x5e>;

			iris {
				compatible = "qcom,wcn3660";
				clocks = <0x2d>;
				clock-names = "xo";
			};

			smd-edge {
				interrupts = <0x00 0xc6 0x01>;
				qcom,ipc = <0x10 0x08 0x19>;
				qcom,smd-edge = <0x06>;
				label = "riva";

				wcnss {
					compatible = "qcom,wcnss";
					qcom,smd-channels = "WCNSS_CTRL";
					qcom,mmio = <0x5e>;

					bluetooth {
						compatible = "qcom,wcnss-bt";
					};

					wifi {
						compatible = "qcom,wcnss-wlan";
						interrupts = <0x00 0xcb 0x04 0x00 0xca 0x04>;
						interrupt-names = "tx", "rx";
						qcom,smem-states = <0x5f 0x0a 0x5f 0x09>;
						qcom,smem-state-names = "tx-enable", "tx-rings-empty";
					};
				};
			};
		};

		etb@1a01000 {
			compatible = "arm,coresight-etb10", "arm,primecell";
			reg = <0x1a01000 0x1000>;
			clocks = <0x12 0x08>;
			clock-names = "apb_pclk";

			in-ports {

				port {

					endpoint {
						remote-endpoint = <0x60>;
						phandle = <0x62>;
					};
				};
			};
		};

		tpiu@1a03000 {
			compatible = "arm,coresight-tpiu", "arm,primecell";
			reg = <0x1a03000 0x1000>;
			clocks = <0x12 0x08>;
			clock-names = "apb_pclk";

			in-ports {

				port {

					endpoint {
						remote-endpoint = <0x61>;
						phandle = <0x63>;
					};
				};
			};
		};

		replicator {
			compatible = "arm,coresight-static-replicator";
			clocks = <0x12 0x08>;
			clock-names = "apb_pclk";

			out-ports {
				#address-cells = <0x01>;
				#size-cells = <0x00>;

				port@0 {
					reg = <0x00>;

					endpoint {
						remote-endpoint = <0x62>;
						phandle = <0x60>;
					};
				};

				port@1 {
					reg = <0x01>;

					endpoint {
						remote-endpoint = <0x63>;
						phandle = <0x61>;
					};
				};
			};

			in-ports {

				port {

					endpoint {
						remote-endpoint = <0x64>;
						phandle = <0x69>;
					};
				};
			};
		};

		funnel@1a04000 {
			compatible = "arm,coresight-dynamic-funnel", "arm,primecell";
			reg = <0x1a04000 0x1000>;
			clocks = <0x12 0x08>;
			clock-names = "apb_pclk";

			in-ports {
				#address-cells = <0x01>;
				#size-cells = <0x00>;

				port@0 {
					reg = <0x00>;

					endpoint {
						remote-endpoint = <0x65>;
						phandle = <0x6b>;
					};
				};

				port@1 {
					reg = <0x01>;

					endpoint {
						remote-endpoint = <0x66>;
						phandle = <0x6d>;
					};
				};

				port@4 {
					reg = <0x04>;

					endpoint {
						remote-endpoint = <0x67>;
						phandle = <0x6f>;
					};
				};

				port@5 {
					reg = <0x05>;

					endpoint {
						remote-endpoint = <0x68>;
						phandle = <0x71>;
					};
				};
			};

			out-ports {

				port {

					endpoint {
						remote-endpoint = <0x69>;
						phandle = <0x64>;
					};
				};
			};
		};

		etm@1a1c000 {
			compatible = "arm,coresight-etm3x", "arm,primecell";
			reg = <0x1a1c000 0x1000>;
			clocks = <0x12 0x08>;
			clock-names = "apb_pclk";
			cpu = <0x6a>;

			out-ports {

				port {

					endpoint {
						remote-endpoint = <0x6b>;
						phandle = <0x65>;
					};
				};
			};
		};

		etm@1a1d000 {
			compatible = "arm,coresight-etm3x", "arm,primecell";
			reg = <0x1a1d000 0x1000>;
			clocks = <0x12 0x08>;
			clock-names = "apb_pclk";
			cpu = <0x6c>;

			out-ports {

				port {

					endpoint {
						remote-endpoint = <0x6d>;
						phandle = <0x66>;
					};
				};
			};
		};

		etm@1a1e000 {
			compatible = "arm,coresight-etm3x", "arm,primecell";
			reg = <0x1a1e000 0x1000>;
			clocks = <0x12 0x08>;
			clock-names = "apb_pclk";
			cpu = <0x6e>;

			out-ports {

				port {

					endpoint {
						remote-endpoint = <0x6f>;
						phandle = <0x67>;
					};
				};
			};
		};

		etm@1a1f000 {
			compatible = "arm,coresight-etm3x", "arm,primecell";
			reg = <0x1a1f000 0x1000>;
			clocks = <0x12 0x08>;
			clock-names = "apb_pclk";
			cpu = <0x70>;

			out-ports {

				port {

					endpoint {
						remote-endpoint = <0x71>;
						phandle = <0x68>;
					};
				};
			};
		};
	};

	iio-hwmon {
		compatible = "iio-hwmon";
		io-channels = <0x72 0x00 0x01 0x72 0x00 0x02 0x72 0x00 0x04 0x72 0x00 0x0b 0x72 0x00 0x0c 0x72 0x00 0x0d 0x72 0x00 0x0e>;
	};

	aliases {
		serial0 = "/soc/gsbi@16600000/serial@16640000";
		serial1 = "/soc/gsbi@16500000/serial@16540000";
		i2c0 = "/soc/gsbi@12440000/i2c@12460000";
		i2c1 = "/soc/gsbi@12480000/i2c@124a0000";
		i2c2 = "/soc/gsbi@16200000/i2c@16280000";
		i2c3 = "/soc/gsbi@16300000/i2c@16380000";
		spi0 = "/soc/gsbi@1a200000/spi@1a280000";
	};

	chosen {
		stdout-path = "serial0:115200n8";
	};

	leds {
		compatible = "gpio-leds";
		pinctrl-names = "default";
		pinctrl-0 = <0x73>;

		led-user1 {
			label = "apq8064:green:user1";
			color = <0x02>;
			gpios = <0x2c 0x12 0x00>;
			default-state = "on";
		};
	};

	hdmi-out {
		compatible = "hdmi-connector";
		type = "d";

		port {

			endpoint {
				remote-endpoint = <0x74>;
				phandle = <0x58>;
			};
		};
	};

	pwrseq-sdcc4 {
		pinctrl-names = "default";
		pinctrl-0 = <0x75>;
		compatible = "mmc-pwrseq-simple";
		reset-gpios = <0x2c 0x2b 0x01>;
		phandle = <0x49>;
	};

	regulator-ext-3p3v {
		compatible = "regulator-fixed";
		regulator-min-microvolt = <0x325aa0>;
		regulator-max-microvolt = <0x325aa0>;
		regulator-name = "ext_3p3v";
		startup-delay-us = <0x00>;
		gpio = <0x13 0x4d 0x00>;
		enable-active-high;
		regulator-boot-on;
		phandle = <0x47>;
	};
};
